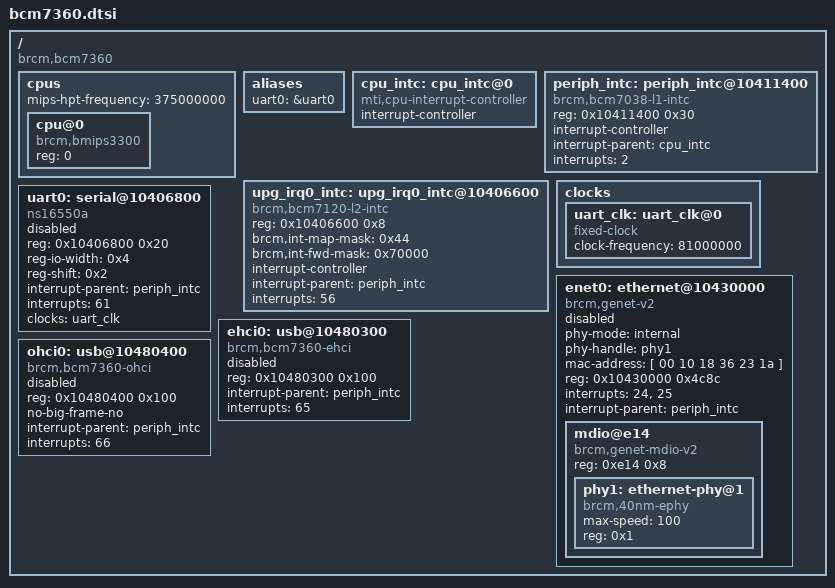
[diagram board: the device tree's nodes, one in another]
/ {
	#address-cells = <1>;
	#size-cells = <1>;
	compatible = "brcm,bcm7360";

	cpus {
		#address-cells = <1>;
		#size-cells = <0>;

		mips-hpt-frequency = <375000000>;

		cpu@0 {
			compatible = "brcm,bmips3300";
			device_type = "cpu";
			reg = <0>;
		};
	};

	aliases {
		uart0 = &uart0;
	};

	cpu_intc: cpu_intc@0 {
		#address-cells = <0>;
		compatible = "mti,cpu-interrupt-controller";

		interrupt-controller;
		#interrupt-cells = <1>;
	};

	periph_intc: periph_intc@10411400 {
		compatible = "brcm,bcm7038-l1-intc";
		reg = <0x10411400 0x30>;

		interrupt-controller;
		#interrupt-cells = <1>;

		interrupt-parent = <&cpu_intc>;
		interrupts = <2>;
	};

	upg_irq0_intc: upg_irq0_intc@10406600 {
		compatible = "brcm,bcm7120-l2-intc";
		reg = <0x10406600 0x8>;

		brcm,int-map-mask = <0x44>;
		brcm,int-fwd-mask = <0x70000>;

		interrupt-controller;
		#interrupt-cells = <1>;

		interrupt-parent = <&periph_intc>;
		interrupts = <56>;
	};

	clocks {
		#address-cells = <1>;
		#size-cells = <0>;

		uart_clk: uart_clk@0 {
			compatible = "fixed-clock";
			#clock-cells = <0>;
			clock-frequency = <81000000>;
		};
	};

	uart0: serial@10406800 {
		compatible = "ns16550a";
		reg = <0x10406800 0x20>;
		reg-io-width = <0x4>;
		reg-shift = <0x2>;
		interrupt-parent = <&periph_intc>;
		interrupts = <61>;
		clocks = <&uart_clk>;
		status = "disabled";
	};

	enet0: ethernet@10430000 {
		phy-mode = "internal";
		phy-handle = <&phy1>;
		mac-address = [ 00 10 18 36 23 1a ];
		compatible = "brcm,genet-v2";
		#address-cells = <0x1>;
		#size-cells = <0x1>;
		reg = <0x10430000 0x4c8c>;
		interrupts = <24>, <25>;
		interrupt-parent = <&periph_intc>;
		status = "disabled";

		mdio@e14 {
			compatible = "brcm,genet-mdio-v2";
			#address-cells = <0x1>;
			#size-cells = <0x0>;
			reg = <0xe14 0x8>;

			phy1: ethernet-phy@1 {
				max-speed = <100>;
				reg = <0x1>;
				compatible = "brcm,40nm-ephy",
					     "ethernet-phy-ieee802.3-c22";
			};
		};
	};

	ehci0: usb@10480300 {
		compatible = "brcm,bcm7360-ehci", "generic-ehci";
		reg = <0x10480300 0x100>;
		interrupt-parent = <&periph_intc>;
		interrupts = <65>;
		status = "disabled";
	};

	ohci0: usb@10480400 {
		compatible = "brcm,bcm7360-ohci", "generic-ohci";
		reg = <0x10480400 0x100>;
		no-big-frame-no;
		interrupt-parent = <&periph_intc>;
		interrupts = <66>;
		status = "disabled";
	};
};
